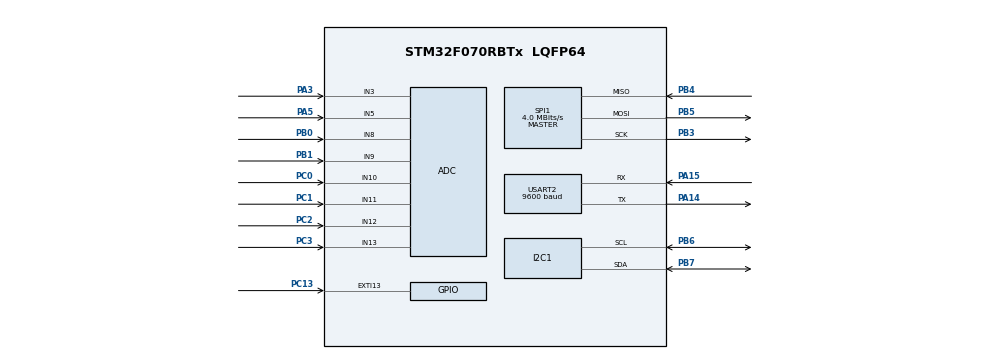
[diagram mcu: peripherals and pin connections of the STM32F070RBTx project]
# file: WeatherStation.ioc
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Mcu.Family=STM32F0
Mcu.Name=STM32F070RBTx
Mcu.Package=LQFP64
NVIC.ADC1_IRQn=true\:0\:0\:false\:false\:true\:true\:true\:true
NVIC.EXTI4_15_IRQn=true\:0\:0\:false\:false\:true\:true\:true\:true
NVIC.I2C1_IRQn=true\:0\:0\:false\:false\:true\:true\:true\:true
NVIC.SPI1_IRQn=true\:0\:0\:false\:false\:true\:true\:true\:true
NVIC.TIM14_IRQn=true\:0\:0\:false\:false\:true\:true\:true\:true
NVIC.TIM16_IRQn=true\:0\:0\:false\:false\:true\:true\:true\:true
NVIC.TIM17_IRQn=true\:0\:0\:false\:false\:true\:true\:true\:true
NVIC.USART2_IRQn=true\:0\:0\:false\:false\:true\:true\:true\:true
PA14.Mode=Asynchronous
PA14.Signal=USART2_TX
PA15.Mode=Asynchronous
PA15.Signal=USART2_RX
PA3.Mode=IN3
PA3.Signal=ADC_IN3
PA5.Mode=IN5
PA5.Signal=ADC_IN5
PB0.Mode=IN8
PB0.Signal=ADC_IN8
PB1.Mode=IN9
PB1.Signal=ADC_IN9
PB3.Mode=Full_Duplex_Master
PB3.Signal=SPI1_SCK
PB4.Mode=Full_Duplex_Master
PB4.Signal=SPI1_MISO
PB5.Mode=Full_Duplex_Master
PB5.Signal=SPI1_MOSI
PB6.Mode=SMBus-two-wire-Interface
PB6.Signal=I2C1_SCL
PB7.Mode=SMBus-two-wire-Interface
PB7.Signal=I2C1_SDA
PC0.Mode=IN10
PC0.Signal=ADC_IN10
PC1.Mode=IN11
PC1.Signal=ADC_IN11
PC13.Signal=GPXTI13
PC2.Mode=IN12
PC2.Signal=ADC_IN12
PC3.Mode=IN13
PC3.Signal=ADC_IN13
ProjectManager.HeapSize=0x200
ProjectManager.StackSize=0x400
ProjectManager.TargetToolchain=MDK-ARM V5.32
SPI1.CalculateBaudRate=4.0 MBits/s
SPI1.Direction=SPI_DIRECTION_2LINES
SPI1.Mode=SPI_MODE_MASTER
SPI1.VirtualType=VM_MASTER
TIM14.Period=500-1
TIM14.Prescaler=8000-1
TIM16.Period=1000-1
TIM16.Prescaler=8000-1
TIM17.Period=1000-1
TIM17.Prescaler=4000-1
USART2.BaudRate=9600
USART2.VirtualMode-Asynchronous=VM_ASYNC
VP_TIM14_VS_ClockSourceINT.Mode=Enable_Timer
VP_TIM16_VS_ClockSourceINT.Mode=Enable_Timer
VP_TIM17_VS_ClockSourceINT.Mode=Enable_Timer
board=custom

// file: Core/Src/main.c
/* USER CODE BEGIN Header */
/**
  ******************************************************************************
  * @file           : main.c
  * @brief          : Main program body
  ******************************************************************************
  * @attention
  *
  * Copyright (c) 2022 STMicroelectronics.
  * All rights reserved.
  *
  * This software is licensed under terms that can be found in the LICENSE file
  * in the root directory of this software component.
  * If no LICENSE file comes with this software, it is provided AS-IS.
  *
  ******************************************************************************
  */
/* USER CODE END Header */
#include "main.h"

ADC_HandleTypeDef hadc;

SMBUS_HandleTypeDef hsmbus1;

SPI_HandleTypeDef hspi1;

TIM_HandleTypeDef htim14;
TIM_HandleTypeDef htim16;
TIM_HandleTypeDef htim17;

UART_HandleTypeDef huart2;

/* USER CODE BEGIN PV */
 uint16_t dhtVal = 0;
 uint16_t uvVal = 0;
 uint16_t tempVal = 0;
 uint16_t humVal = 0;
 uint8_t rxbuffer[5];
 uint8_t txbuffer[15]="00//" + (char)dhtVal;
 uint32_t dataBuffer[5];
/* USER CODE END PV */

void SystemClock_Config(void);
static void MX_GPIO_Init(void);
static void MX_ADC_Init(void);
static void MX_I2C1_SMBUS_Init(void);
static void MX_SPI1_Init(void);
static void MX_TIM14_Init(void);
static void MX_TIM16_Init(void);
static void MX_TIM17_Init(void);
static void MX_USART2_UART_Init(void);

/* USER CODE BEGIN 0 */
void HAL_TIM_PeriodElapsedCallback(TIM_HandleTypeDef *htim)
{

}

 void HAL_UART_RxCpltCallback(UART_HandleTypeDef *huart)
{
  HAL_UART_Transmit(&huart2,(uint8_t*)txbuffer,sizeof(txbuffer),50);
	HAL_GPIO_TogglePin(GPIOA,GPIO_PIN_5);
	//transmits for 50millisecs

	HAL_UART_Receive_IT(&huart2,(uint8_t*)rxbuffer,5);
	//receives 5 characters
}

/* USER CODE END 0 */

int main(void)
{

  /* MCU Configuration--------------------------------------------------------*/

  /* Reset of all peripherals, Initializes the Flash interface and the Systick. */
  HAL_Init();

  /* Configure the system clock */
  SystemClock_Config();

  /* Initialize all configured peripherals */
  MX_GPIO_Init();
  MX_ADC_Init();
  MX_I2C1_SMBUS_Init();
  MX_SPI1_Init();
  MX_TIM14_Init();
  MX_TIM16_Init();
  MX_TIM17_Init();
  MX_USART2_UART_Init();
  /* USER CODE BEGIN 2 */
	HAL_UART_Receive_IT(&huart2,(uint8_t*)rxbuffer,5);
  /* USER CODE END 2 */

  /* Infinite loop */
  while (1)
  {
				//ADC pin is PA0 (A0 on STM32 board)
		//give GND to PA0 and observe ~0 counts, Apply 3.3V and observe ~4096 counts, MAKE SURE THAT YOU DON'T APPLY 5V to any pin
		HAL_ADC_Start(&hadc);
		HAL_ADC_PollForConversion(&hadc,50);//wiat till max is 50ms
		dhtVal = HAL_ADC_GetValue(&hadc);

		HAL_ADC_Stop(&hadc);
		HAL_Delay(500);
  }
}

void SystemClock_Config(void)
{
  RCC_OscInitTypeDef RCC_OscInitStruct = {0};
  RCC_ClkInitTypeDef RCC_ClkInitStruct = {0};
  RCC_PeriphCLKInitTypeDef PeriphClkInit = {0};

  /** Initializes the RCC Oscillators according to the specified parameters
  * in the RCC_OscInitTypeDef structure.
  */
  RCC_OscInitStruct.OscillatorType = RCC_OSCILLATORTYPE_HSI|RCC_OSCILLATORTYPE_HSI14;
  RCC_OscInitStruct.HSIState = RCC_HSI_ON;
  RCC_OscInitStruct.HSI14State = RCC_HSI14_ON;
  RCC_OscInitStruct.HSICalibrationValue = RCC_HSICALIBRATION_DEFAULT;
  RCC_OscInitStruct.HSI14CalibrationValue = 16;
  RCC_OscInitStruct.PLL.PLLState = RCC_PLL_NONE;
  if (HAL_RCC_OscConfig(&RCC_OscInitStruct) != HAL_OK)
  {
    Error_Handler();
  }

  /** Initializes the CPU, AHB and APB buses clocks
  */
  RCC_ClkInitStruct.ClockType = RCC_CLOCKTYPE_HCLK|RCC_CLOCKTYPE_SYSCLK
                              |RCC_CLOCKTYPE_PCLK1;
  RCC_ClkInitStruct.SYSCLKSource = RCC_SYSCLKSOURCE_HSI;
  RCC_ClkInitStruct.AHBCLKDivider = RCC_SYSCLK_DIV1;
  RCC_ClkInitStruct.APB1CLKDivider = RCC_HCLK_DIV1;

  if (HAL_RCC_ClockConfig(&RCC_ClkInitStruct, FLASH_LATENCY_0) != HAL_OK)
  {
    Error_Handler();
  }
  PeriphClkInit.PeriphClockSelection = RCC_PERIPHCLK_I2C1;
  PeriphClkInit.I2c1ClockSelection = RCC_I2C1CLKSOURCE_HSI;
  if (HAL_RCCEx_PeriphCLKConfig(&PeriphClkInit) != HAL_OK)
  {
    Error_Handler();
  }
}

static void MX_ADC_Init(void)
{

  ADC_ChannelConfTypeDef sConfig = {0};

  /** Configure the global features of the ADC (Clock, Resolution, Data Alignment and number of conversion)
  */
  hadc.Instance = ADC1;
  hadc.Init.ClockPrescaler = ADC_CLOCK_ASYNC_DIV1;
  hadc.Init.Resolution = ADC_RESOLUTION_12B;
  hadc.Init.DataAlign = ADC_DATAALIGN_RIGHT;
  hadc.Init.ScanConvMode = ADC_SCAN_DIRECTION_FORWARD;
  hadc.Init.EOCSelection = ADC_EOC_SINGLE_CONV;
  hadc.Init.LowPowerAutoWait = DISABLE;
  hadc.Init.LowPowerAutoPowerOff = DISABLE;
  hadc.Init.ContinuousConvMode = DISABLE;
  hadc.Init.DiscontinuousConvMode = DISABLE;
  hadc.Init.ExternalTrigConv = ADC_SOFTWARE_START;
  hadc.Init.ExternalTrigConvEdge = ADC_EXTERNALTRIGCONVEDGE_NONE;
  hadc.Init.DMAContinuousRequests = DISABLE;
  hadc.Init.Overrun = ADC_OVR_DATA_PRESERVED;
  if (HAL_ADC_Init(&hadc) != HAL_OK)
  {
    Error_Handler();
  }

  /** Configure for the selected ADC regular channel to be converted.
  */
  sConfig.Channel = ADC_CHANNEL_3;
  sConfig.Rank = ADC_RANK_CHANNEL_NUMBER;
  sConfig.SamplingTime = ADC_SAMPLETIME_1CYCLE_5;
  if (HAL_ADC_ConfigChannel(&hadc, &sConfig) != HAL_OK)
  {
    Error_Handler();
  }

  /** Configure for the selected ADC regular channel to be converted.
  */
  sConfig.Channel = ADC_CHANNEL_5;
  if (HAL_ADC_ConfigChannel(&hadc, &sConfig) != HAL_OK)
  {
    Error_Handler();
  }

  /** Configure for the selected ADC regular channel to be converted.
  */
  sConfig.Channel = ADC_CHANNEL_8;
  if (HAL_ADC_ConfigChannel(&hadc, &sConfig) != HAL_OK)
  {
    Error_Handler();
  }

  /** Configure for the selected ADC regular channel to be converted.
  */
  sConfig.Channel = ADC_CHANNEL_9;
  if (HAL_ADC_ConfigChannel(&hadc, &sConfig) != HAL_OK)
  {
    Error_Handler();
  }

  /** Configure for the selected ADC regular channel to be converted.
  */
  sConfig.Channel = ADC_CHANNEL_10;
  if (HAL_ADC_ConfigChannel(&hadc, &sConfig) != HAL_OK)
  {
    Error_Handler();
  }

  /** Configure for the selected ADC regular channel to be converted.
  */
  sConfig.Channel = ADC_CHANNEL_11;
  if (HAL_ADC_ConfigChannel(&hadc, &sConfig) != HAL_OK)
  {
    Error_Handler();
  }

  /** Configure for the selected ADC regular channel to be converted.
  */
  sConfig.Channel = ADC_CHANNEL_12;
  if (HAL_ADC_ConfigChannel(&hadc, &sConfig) != HAL_OK)
  {
    Error_Handler();
  }

  /** Configure for the selected ADC regular channel to be converted.
  */
  sConfig.Channel = ADC_CHANNEL_13;
  if (HAL_ADC_ConfigChannel(&hadc, &sConfig) != HAL_OK)
  {
    Error_Handler();
  }

}

static void MX_I2C1_SMBUS_Init(void)
{

  hsmbus1.Instance = I2C1;
  hsmbus1.Init.Timing = 0x2000090E;
  hsmbus1.Init.AnalogFilter = SMBUS_ANALOGFILTER_ENABLE;
  hsmbus1.Init.OwnAddress1 = 2;
  hsmbus1.Init.AddressingMode = SMBUS_ADDRESSINGMODE_7BIT;
  hsmbus1.Init.DualAddressMode = SMBUS_DUALADDRESS_DISABLE;
  hsmbus1.Init.OwnAddress2 = 0;
  hsmbus1.Init.OwnAddress2Masks = SMBUS_OA2_NOMASK;
  hsmbus1.Init.GeneralCallMode = SMBUS_GENERALCALL_DISABLE;
  hsmbus1.Init.NoStretchMode = SMBUS_NOSTRETCH_DISABLE;
  hsmbus1.Init.PacketErrorCheckMode = SMBUS_PEC_DISABLE;
  hsmbus1.Init.PeripheralMode = SMBUS_PERIPHERAL_MODE_SMBUS_SLAVE;
  hsmbus1.Init.SMBusTimeout = 0x00008061;
  if (HAL_SMBUS_Init(&hsmbus1) != HAL_OK)
  {
    Error_Handler();
  }

}

static void MX_SPI1_Init(void)
{

  /* SPI1 parameter configuration*/
  hspi1.Instance = SPI1;
  hspi1.Init.Mode = SPI_MODE_MASTER;
  hspi1.Init.Direction = SPI_DIRECTION_2LINES;
  hspi1.Init.DataSize = SPI_DATASIZE_4BIT;
  hspi1.Init.CLKPolarity = SPI_POLARITY_LOW;
  hspi1.Init.CLKPhase = SPI_PHASE_1EDGE;
  hspi1.Init.NSS = SPI_NSS_SOFT;
  hspi1.Init.BaudRatePrescaler = SPI_BAUDRATEPRESCALER_2;
  hspi1.Init.FirstBit = SPI_FIRSTBIT_MSB;
  hspi1.Init.TIMode = SPI_TIMODE_DISABLE;
  hspi1.Init.CRCCalculation = SPI_CRCCALCULATION_DISABLE;
  hspi1.Init.CRCPolynomial = 7;
  hspi1.Init.CRCLength = SPI_CRC_LENGTH_DATASIZE;
  hspi1.Init.NSSPMode = SPI_NSS_PULSE_ENABLE;
  if (HAL_SPI_Init(&hspi1) != HAL_OK)
  {
    Error_Handler();
  }

}

static void MX_TIM14_Init(void)
{

  htim14.Instance = TIM14;
  htim14.Init.Prescaler = 8000-1;
  htim14.Init.CounterMode = TIM_COUNTERMODE_UP;
  htim14.Init.Period = 500-1;
  htim14.Init.ClockDivision = TIM_CLOCKDIVISION_DIV1;
  htim14.Init.AutoReloadPreload = TIM_AUTORELOAD_PRELOAD_DISABLE;
  if (HAL_TIM_Base_Init(&htim14) != HAL_OK)
  {
    Error_Handler();
  }

}

static void MX_TIM16_Init(void)
{

  htim16.Instance = TIM16;
  htim16.Init.Prescaler = 8000-1;
  htim16.Init.CounterMode = TIM_COUNTERMODE_UP;
  htim16.Init.Period = 1000-1;
  htim16.Init.ClockDivision = TIM_CLOCKDIVISION_DIV1;
  htim16.Init.RepetitionCounter = 0;
  htim16.Init.AutoReloadPreload = TIM_AUTORELOAD_PRELOAD_DISABLE;
  if (HAL_TIM_Base_Init(&htim16) != HAL_OK)
  {
    Error_Handler();
  }

}

static void MX_TIM17_Init(void)
{

  htim17.Instance = TIM17;
  htim17.Init.Prescaler = 4000-1;
  htim17.Init.CounterMode = TIM_COUNTERMODE_UP;
  htim17.Init.Period = 1000-1;
  htim17.Init.ClockDivision = TIM_CLOCKDIVISION_DIV1;
  htim17.Init.RepetitionCounter = 0;
  htim17.Init.AutoReloadPreload = TIM_AUTORELOAD_PRELOAD_DISABLE;
  if (HAL_TIM_Base_Init(&htim17) != HAL_OK)
  {
    Error_Handler();
  }

}

static void MX_USART2_UART_Init(void)
{

  huart2.Instance = USART2;
  huart2.Init.BaudRate = 9600;
  huart2.Init.WordLength = UART_WORDLENGTH_8B;
  huart2.Init.StopBits = UART_STOPBITS_1;
  huart2.Init.Parity = UART_PARITY_NONE;
  huart2.Init.Mode = UART_MODE_TX_RX;
  huart2.Init.HwFlowCtl = UART_HWCONTROL_NONE;
  huart2.Init.OverSampling = UART_OVERSAMPLING_16;
  huart2.Init.OneBitSampling = UART_ONE_BIT_SAMPLE_DISABLE;
  huart2.AdvancedInit.AdvFeatureInit = UART_ADVFEATURE_NO_INIT;
  if (HAL_UART_Init(&huart2) != HAL_OK)
  {
    Error_Handler();
  }

}

static void MX_GPIO_Init(void)
{
  GPIO_InitTypeDef GPIO_InitStruct = {0};

  /* GPIO Ports Clock Enable */
  __HAL_RCC_GPIOC_CLK_ENABLE();
  __HAL_RCC_GPIOA_CLK_ENABLE();
  __HAL_RCC_GPIOB_CLK_ENABLE();

  /*Configure GPIO pin : PC13 */
  GPIO_InitStruct.Pin = GPIO_PIN_13;
  GPIO_InitStruct.Mode = GPIO_MODE_IT_RISING;
  GPIO_InitStruct.Pull = GPIO_NOPULL;
  HAL_GPIO_Init(GPIOC, &GPIO_InitStruct);

  /* EXTI interrupt init*/
  HAL_NVIC_SetPriority(EXTI4_15_IRQn, 0, 0);
  HAL_NVIC_EnableIRQ(EXTI4_15_IRQn);

}

void Error_Handler(void)
{
  __disable_irq();
  while (1)
  {
  }
}
